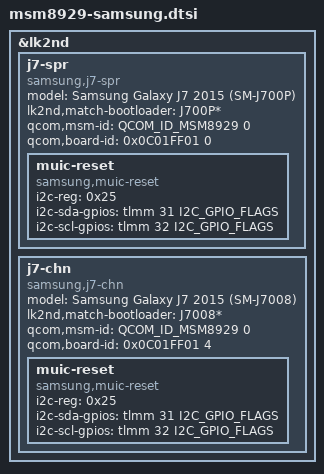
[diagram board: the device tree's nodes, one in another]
// SPDX-License-Identifier: BSD-3-Clause

&lk2nd {
	/* rev 0 */

	j7-spr {
		model = "Samsung Galaxy J7 2015 (SM-J700P)";
		compatible = "samsung,j7-spr", "samsung,j7";
		lk2nd,match-bootloader = "J700P*";

		// FIXME: lk2nd,dtb-files = "msm8929-samsung-j7";

		qcom,msm-id = <QCOM_ID_MSM8929 0>;
		qcom,board-id = <0x0C01FF01 0>;

		muic-reset {
			compatible = "samsung,muic-reset";
			i2c-reg = <0x25>;
			i2c-sda-gpios = <&tlmm 31 I2C_GPIO_FLAGS>;
			i2c-scl-gpios = <&tlmm 32 I2C_GPIO_FLAGS>;
		};
	};

	/* rev 4 */

	j7-chn {
		model = "Samsung Galaxy J7 2015 (SM-J7008)";
		compatible = "samsung,j7-chn", "samsung,j7";
		lk2nd,match-bootloader = "J7008*";

		// FIXME: lk2nd,dtb-files = "msm8929-samsung-j7";

		qcom,msm-id = <QCOM_ID_MSM8929 0>;
		qcom,board-id = <0x0C01FF01 4>;

		muic-reset {
			compatible = "samsung,muic-reset";
			i2c-reg = <0x25>;
			i2c-sda-gpios = <&tlmm 31 I2C_GPIO_FLAGS>;
			i2c-scl-gpios = <&tlmm 32 I2C_GPIO_FLAGS>;
		};
	};
};
